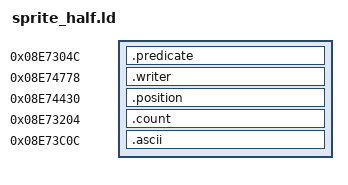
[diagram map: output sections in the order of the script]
SECTIONS {
 .predicate 0x08e7304c : { *(.predicate) }
 .writer 0x08e74778 : { *(.writer) }
 .position 0x08e74430 : { *(.position) }
 .count 0x08e73204 : { *(.count) }
 .ascii 0x08e73c0c : { *(.ascii) }
}
